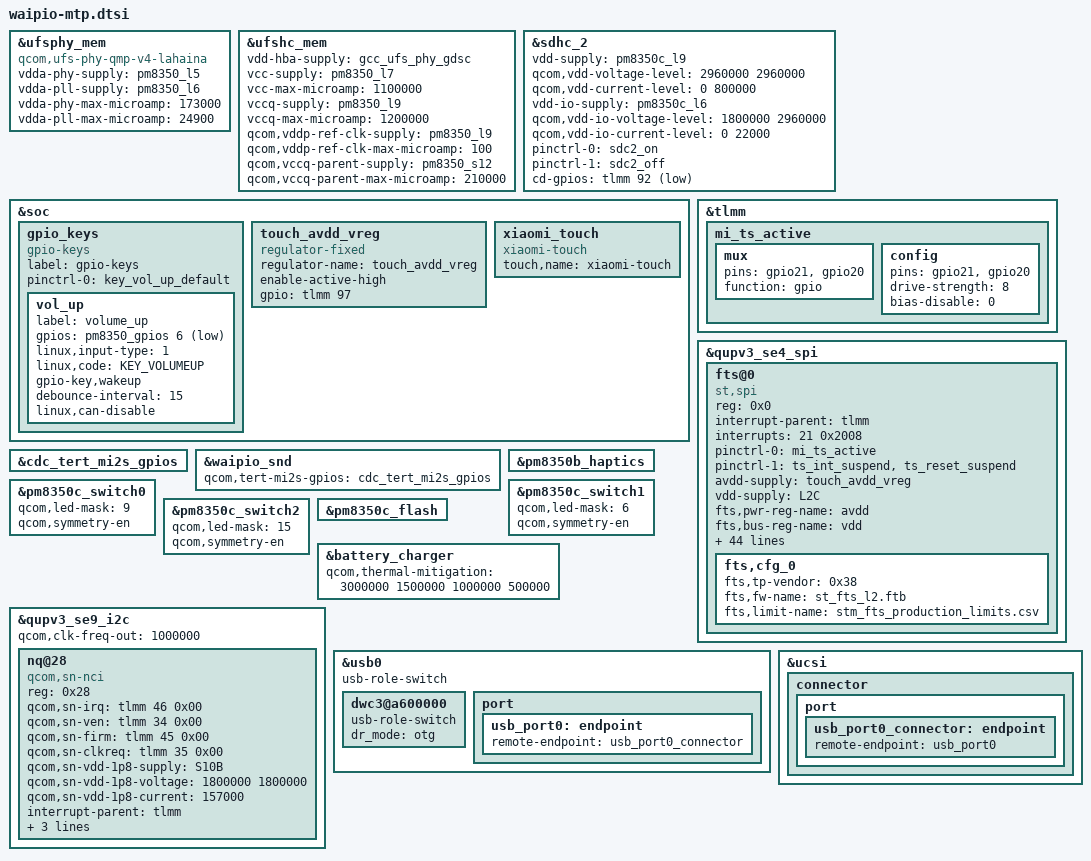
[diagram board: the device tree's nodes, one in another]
#include <dt-bindings/gpio/gpio.h>
#include <dt-bindings/input/input.h>

#include "waipio-pmic-overlay.dtsi"
#include "waipio-thermal-overlay.dtsi"
#include "waipio-audio-overlay.dtsi"

&ufsphy_mem {
	compatible = "qcom,ufs-phy-qmp-v4-lahaina";

	vdda-phy-supply = <&pm8350_l5>;
	vdda-pll-supply = <&pm8350_l6>;
	vdda-phy-max-microamp = <173000>;
	vdda-pll-max-microamp = <24900>;

	status = "ok";
};

&ufshc_mem {
	vdd-hba-supply = <&gcc_ufs_phy_gdsc>;

	vcc-supply = <&pm8350_l7>;
	vcc-max-microamp = <1100000>;

	vccq-supply = <&pm8350_l9>;
	vccq-max-microamp = <1200000>;

	qcom,vddp-ref-clk-supply = <&pm8350_l9>;
	qcom,vddp-ref-clk-max-microamp = <100>;

	qcom,vccq-parent-supply = <&pm8350_s12>;
	qcom,vccq-parent-max-microamp = <210000>;

	status = "ok";
};

&sdhc_2 {
	status = "ok";
	vdd-supply = <&pm8350c_l9>;
	qcom,vdd-voltage-level = <2960000 2960000>;
	qcom,vdd-current-level = <0 800000>;

	vdd-io-supply = <&pm8350c_l6>;
	qcom,vdd-io-voltage-level = <1800000 2960000>;
	qcom,vdd-io-current-level = <0 22000>;

	pinctrl-names = "default", "sleep";
	pinctrl-0 = <&sdc2_on>;
	pinctrl-1 = <&sdc2_off>;

	cd-gpios = <&tlmm 92 GPIO_ACTIVE_LOW>;
};

&soc {
	gpio_keys {
		compatible = "gpio-keys";
		label = "gpio-keys";

		pinctrl-names = "default";
		pinctrl-0 = <&key_vol_up_default>;

		vol_up {
			label = "volume_up";
			gpios = <&pm8350_gpios 6 GPIO_ACTIVE_LOW>;
			linux,input-type = <1>;
			linux,code = <KEY_VOLUMEUP>;
			gpio-key,wakeup;
			debounce-interval = <15>;
			linux,can-disable;
		};
	};

	touch_avdd_vreg: touch_avdd_vreg {
		compatible = "regulator-fixed";
		regulator-name = "touch_avdd_vreg";
		enable-active-high;
		gpio = <&tlmm 97 0>;
	};

	xiaomi_touch {
		compatible = "xiaomi-touch";
		status = "ok";
		touch,name = "xiaomi-touch";
	};
};



&tlmm {
	mi_ts_active: mi_ts_active {
		mux {
				pins = "gpio21", "gpio20";
				function = "gpio";
		};

		config {
				pins = "gpio21", "gpio20";
				drive-strength = <8>;
				bias-disable = <0>;
		};
	};
};



&qupv3_se4_spi {
	status = "ok";
	fts@0 {
		status = "ok";
		compatible = "st,spi";
		reg = <0x0>;
		interrupt-parent = <&tlmm>;
		interrupts = <21 0x2008>;
		pinctrl-names = "pmx_ts_active", "pmx_ts_suspend";
		pinctrl-0 = <&mi_ts_active>;
		pinctrl-1 = <&ts_int_suspend &ts_reset_suspend>;
		avdd-supply = <&touch_avdd_vreg>;
		vdd-supply = <&L2C>;
		fts,pwr-reg-name = "avdd";
		fts,bus-reg-name = "vdd";
		fts,irq-gpio = <&tlmm 21 0x2008>;
		fts,irq-gpio-name = "fts_irq";
		fts,reset-gpio-enable;
		fts,reset-gpio = <&tlmm 20 0x00>;
		fts,reset-gpio-name = "fts_rst";
		fts,irq-flags = <0x2008>;
		fts,x-max = <1440>;
		fts,y-max = <3200>;
		fts,fod-lx = <588>;
		fts,fod-ly = <2358>;
		fts,fod-x-size = <264>;
		fts,fod-y-size = <264>;
		fts,support-fod;
		spi-max-frequency = <7000000>;
		/*fts,default-fw-name = "st_fts_l2.ftb";*/
		fts,htp-fw-name = "st_fts_k2_htp.ftb";
		fts,config-array-size = <1>;
		fts,touch-follow-performance-def = <3>;
		fts,touch-tap-sensitivity-def = <4>;
		fts,touch-aim-sensitivity-def = <3>;
		fts,touch-tap-stability-def = <3>;
		fts,cornerfilter-area-step1 = <150>;
		fts,cornerfilter-area-step2 = <280>;
		fts,cornerfilter-area-step3 = <400>;
		fts,touch-deadzone-filter-ver = <2 0 0 0 0 0 0 0
										2 1 0 0 0 0 0 0
										2 2 0 0 0 3199 0 0
										2 3 1439 0 1439 3199 0 0>;
		fts,touch-deadzone-filter-hor = <2 0 0 0 1439 7 0 0
										2 1 0 3192 1439 3199 0 0
										2 2 0 0 0 3199 0 0
										2 3 1439 0 1439 3199 0 0>;
		fts,touch-edgezone-filter-ver = <1 0 0 0 0 0 0 0
										1 1 0 0 0 0 0 0
										1 2 0 0 60 3199 0 0
										1 3 1379 0 1439 3199 0 0>;
		fts,touch-edgezone-filter-hor = <1 0 0 0 1439 70 0 0
										1 1 0 3129 1439 3199 0 0
										1 2 0 0 60 3199 0 0
										1 3 1379 0 1439 3199 0 0>;
		fts,touch-cornerzone-filter-ver = <0 0 0 0 0 0 0 0
										0 1 0 0 0 0 0 0
										0 2 0 2799 250 3199 0 0
										0 3 1189 2799 1439 3199 0 0>;
		fts,touch-cornerzone-filter-hor1 = <0 0 0 0 280 280 0 0
										0 1 0 0 0 0 0 0
										0 2 0 2919 280 3199 0 0
										0 3 0 0 0 0 0 0>;
		fts,touch-cornerzone-filter-hor2 = <0 0 0 0 0 0 0 0
										0 1 1159 0 1439 280 0 0
										0 2 0 0 0 0 0 0
										0 3 1159 2919 1439 3199 0 0>;
		fts,touch-follow-performance = <10 15 1
										8 15 1
										6 15 1
										4 15 1
										2 15 1>;
		fts,touch-tap-sensitivity = <160 150 140 120 100>;
		fts,touch-aim-sensitivity = <10 8 6 4 2>;
		fts,touch-tap-stability = <8 12 15 18 25>;
		fts,touch-expert-array = <6 15 1 120 6 15
								  2 15 1 120 4 15
								  4 15 1 120 2 15>;
		fts,cfg_0 {
			fts,tp-vendor = <0x38>;
			fts,fw-name = "st_fts_l2.ftb";
			fts,limit-name = "stm_fts_production_limits.csv";
		};
	};
};


&cdc_tert_mi2s_gpios {
	status = "ok";
};

&waipio_snd {
	qcom,tert-mi2s-gpios = <&cdc_tert_mi2s_gpios>;
};

&pm8350b_haptics {
	status = "ok";
};

&pm8350c_switch0 {
	qcom,led-mask = <9>; /* Channels 1 & 4 */
	qcom,symmetry-en;
};

&pm8350c_switch1 {
	qcom,led-mask = <6>; /* Channels 2 & 3 */
	qcom,symmetry-en;
};

&pm8350c_switch2 {
	qcom,led-mask = <15>; /* All Channels */
	qcom,symmetry-en;
};

&pm8350c_flash {
	status = "ok";
};

&battery_charger {
	qcom,thermal-mitigation = <3000000 1500000 1000000 500000>;
};

&qupv3_se9_i2c {
	status = "ok";
	qcom,clk-freq-out = <1000000>;
	#address-cells = <1>;
	#size-cells = <0>;
	nq@28 {
		compatible = "qcom,sn-nci";
		reg = <0x28>;
		qcom,sn-irq = <&tlmm 46 0x00>;
		qcom,sn-ven = <&tlmm 34 0x00>;
		qcom,sn-firm = <&tlmm 45 0x00>;
		qcom,sn-clkreq = <&tlmm 35 0x00>;
		qcom,sn-vdd-1p8-supply = <&S10B>;
		qcom,sn-vdd-1p8-voltage = <1800000 1800000>;
		qcom,sn-vdd-1p8-current = <157000>;
		interrupt-parent = <&tlmm>;
		interrupts = <46 0>;
		interrupt-names = "nfc_irq";
		pinctrl-names = "nfc_active", "nfc_suspend";
		pinctrl-0 = <&nfc_int_active &nfc_enable_active>;
		pinctrl-1 = <&nfc_int_suspend &nfc_enable_suspend>;
	};
};

&usb0 {
	usb-role-switch;

	dwc3@a600000 {
		usb-role-switch;
		dr_mode = "otg";
	};

	port {
		usb_port0: endpoint {
			remote-endpoint = <&usb_port0_connector>;
		};
	};
};

&ucsi {
	connector {
		port {
			usb_port0_connector: endpoint {
				remote-endpoint = <&usb_port0>;
			};
		};
	};
};
